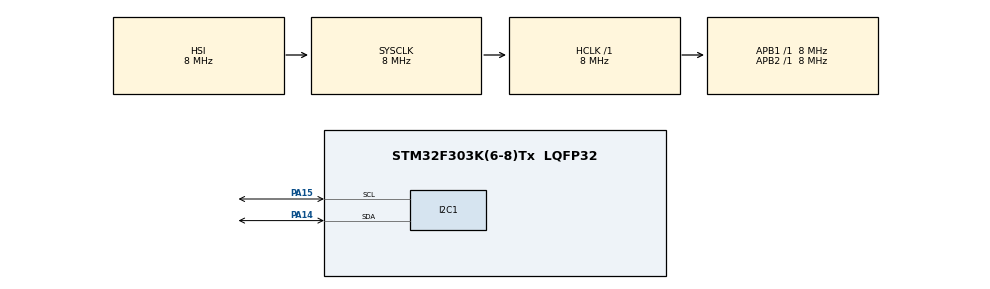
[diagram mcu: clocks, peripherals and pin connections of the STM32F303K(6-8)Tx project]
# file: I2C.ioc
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I2C1.Timing=0x00201D2B
Mcu.Family=STM32F3
Mcu.Name=STM32F303K(6-8)Tx
Mcu.Package=LQFP32
NVIC.PriorityGroup=NVIC_PRIORITYGROUP_4
PA14.Mode=I2C
PA14.Signal=I2C1_SDA
PA15.Mode=I2C
PA15.Signal=I2C1_SCL
ProjectManager.HeapSize=0x200
ProjectManager.StackSize=0x400
ProjectManager.TargetToolchain=STM32CubeIDE
RCC.AHBFreq_Value=8000000
RCC.APB1Freq_Value=8000000
RCC.APB2Freq_Value=8000000
RCC.CortexFreq_Value=8000000
RCC.HSE_VALUE=8000000
RCC.HSI_VALUE=8000000
RCC.SYSCLKFreq_VALUE=8000000
board=custom

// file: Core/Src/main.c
/* USER CODE BEGIN Header */
/**
  ******************************************************************************
  * @file           : main.c
  * @brief          : Main program body
  ******************************************************************************
  * @attention
  *
  * Copyright (c) 2026 STMicroelectronics.
  * All rights reserved.
  *
  * This software is licensed under terms that can be found in the LICENSE file
  * in the root directory of this software component.
  * If no LICENSE file comes with this software, it is provided AS-IS.
  *
  ******************************************************************************
  */
/* USER CODE END Header */
#include "main.h"

/* USER CODE BEGIN PD */

#define WRITE_ADDRESS 0xD0   // DS3231 7-bit adres: 0x68 → HAL için <<1
#define READ_ADDRESS  0xD1

/* USER CODE END PD */

I2C_HandleTypeDef hi2c1;

/* USER CODE BEGIN PV */
typedef struct
{
	uint8_t second ;
	uint8_t minute;
	uint8_t hour;
	uint8_t dayofweek;
	uint8_t dayofmount;
	uint8_t mounth;
	uint8_t year;
}DS3231_Time_t;

DS3231_Time_t ds3231time;
/* USER CODE END PV */

void SystemClock_Config(void);
static void MX_GPIO_Init(void);
static void MX_I2C1_Init(void);

/* USER CODE BEGIN 0 */
// ds3231 için bu
uint8_t DEC_to_BCD(uint8_t value)
{
return (uint8_t)((value /10*16)+(value%10));
}

uint8_t BCD_to_DEC(uint8_t value)
{
return (uint8_t)((value /16*10)+(value%16));
}

// ds3231 için

void ds3231_set_time(uint8_t second ,uint8_t minute,uint8_t hour ,uint8_t dayofweek , uint8_t dayofmount , uint8_t mounth , uint8_t year )
{

	uint8_t time_data[7] = {0};
	time_data[0]= DEC_to_BCD(second);
	time_data[1]= DEC_to_BCD(minute);
	time_data[2]= DEC_to_BCD(hour);
	time_data[3]= DEC_to_BCD(dayofweek);
	time_data[4]= DEC_to_BCD(dayofmount);
	time_data[5]= DEC_to_BCD(mounth);
	time_data[6]= DEC_to_BCD(year);
	HAL_I2C_Mem_Write(&hi2c1, WRITE_ADDRESS, 0x00, 1, time_data , 7, 100);
}

DS3231_Time_t ds3231_get_time(void)

{

	DS3231_Time_t dsTime = {0};
	uint8_t receive_time[7] = {0};
	if(HAL_I2C_Mem_Read(&hi2c1, READ_ADDRESS, 0x00, 1, receive_time , 7, 100)==HAL_OK)

	{

		dsTime.second     = BCD_to_DEC(receive_time[0]);
		dsTime.minute     = BCD_to_DEC(receive_time[1]);
		dsTime.hour       = BCD_to_DEC(receive_time[2]);
		dsTime.dayofweek  = BCD_to_DEC(receive_time[3]);
		dsTime.dayofmount = BCD_to_DEC(receive_time[4]);
		dsTime.mounth     = BCD_to_DEC(receive_time[5]);
		dsTime.year       = BCD_to_DEC(receive_time[6]) + 2000;

	}

	return dsTime;
}
/* USER CODE END 0 */

int main(void)
{

  /* MCU Configuration--------------------------------------------------------*/

  /* Reset of all peripherals, Initializes the Flash interface and the Systick. */
  HAL_Init();

  /* Configure the system clock */
  SystemClock_Config();

  /* Initialize all configured peripherals */
  MX_GPIO_Init();
  MX_I2C1_Init();
  /* USER CODE BEGIN 2 */
/*
  uint8_t address = 0;
  	  for(int i = 0; i<255 ; i++)
  	  {

  		 if(HAL_I2C_IsDeviceReady(&hi2c1, i, 1, 100) == HAL_OK)
  		 {

  			 address = i;
  		 }

  	  }
  	  */

  ds3231_set_time(0, 0, 12, 3, 13, 6, 35);

  /* USER CODE END 2 */

  /* Infinite loop */
  while (1)
  {
	  ds3231time = ds3231_get_time();
	  HAL_Delay(3000);

  }
}

void SystemClock_Config(void)
{
  RCC_OscInitTypeDef RCC_OscInitStruct = {0};
  RCC_ClkInitTypeDef RCC_ClkInitStruct = {0};
  RCC_PeriphCLKInitTypeDef PeriphClkInit = {0};

  /** Initializes the RCC Oscillators according to the specified parameters
  * in the RCC_OscInitTypeDef structure.
  */
  RCC_OscInitStruct.OscillatorType = RCC_OSCILLATORTYPE_HSI;
  RCC_OscInitStruct.HSIState = RCC_HSI_ON;
  RCC_OscInitStruct.HSICalibrationValue = RCC_HSICALIBRATION_DEFAULT;
  RCC_OscInitStruct.PLL.PLLState = RCC_PLL_NONE;
  if (HAL_RCC_OscConfig(&RCC_OscInitStruct) != HAL_OK)
  {
    Error_Handler();
  }

  /** Initializes the CPU, AHB and APB buses clocks
  */
  RCC_ClkInitStruct.ClockType = RCC_CLOCKTYPE_HCLK|RCC_CLOCKTYPE_SYSCLK
                              |RCC_CLOCKTYPE_PCLK1|RCC_CLOCKTYPE_PCLK2;
  RCC_ClkInitStruct.SYSCLKSource = RCC_SYSCLKSOURCE_HSI;
  RCC_ClkInitStruct.AHBCLKDivider = RCC_SYSCLK_DIV1;
  RCC_ClkInitStruct.APB1CLKDivider = RCC_HCLK_DIV1;
  RCC_ClkInitStruct.APB2CLKDivider = RCC_HCLK_DIV1;

  if (HAL_RCC_ClockConfig(&RCC_ClkInitStruct, FLASH_LATENCY_0) != HAL_OK)
  {
    Error_Handler();
  }
  PeriphClkInit.PeriphClockSelection = RCC_PERIPHCLK_I2C1;
  PeriphClkInit.I2c1ClockSelection = RCC_I2C1CLKSOURCE_HSI;
  if (HAL_RCCEx_PeriphCLKConfig(&PeriphClkInit) != HAL_OK)
  {
    Error_Handler();
  }
}

static void MX_I2C1_Init(void)
{

  hi2c1.Instance = I2C1;
  hi2c1.Init.Timing = 0x00201D2B;
  hi2c1.Init.OwnAddress1 = 0;
  hi2c1.Init.AddressingMode = I2C_ADDRESSINGMODE_7BIT;
  hi2c1.Init.DualAddressMode = I2C_DUALADDRESS_DISABLE;
  hi2c1.Init.OwnAddress2 = 0;
  hi2c1.Init.OwnAddress2Masks = I2C_OA2_NOMASK;
  hi2c1.Init.GeneralCallMode = I2C_GENERALCALL_DISABLE;
  hi2c1.Init.NoStretchMode = I2C_NOSTRETCH_DISABLE;
  if (HAL_I2C_Init(&hi2c1) != HAL_OK)
  {
    Error_Handler();
  }

  /** Configure Analogue filter
  */
  if (HAL_I2CEx_ConfigAnalogFilter(&hi2c1, I2C_ANALOGFILTER_ENABLE) != HAL_OK)
  {
    Error_Handler();
  }

  /** Configure Digital filter
  */
  if (HAL_I2CEx_ConfigDigitalFilter(&hi2c1, 0) != HAL_OK)
  {
    Error_Handler();
  }

}

static void MX_GPIO_Init(void)
{

  /* GPIO Ports Clock Enable */
  __HAL_RCC_GPIOA_CLK_ENABLE();

}

void Error_Handler(void)
{
  __disable_irq();
  while (1)
  {
  }
}
